# MKM34Z7 register map
Vendor: Freescale Semiconductor, Inc.; Series: Kinetis_M; File version: 1.6
CPU: CM0PLUS r0p0, little endian, no MPU, no FPU, VTOR, 2 interrupt priority bits
Registers are 8-bit, read-write, reset 0x0 unless marked. A register's access mark holds for its fields unless they carry their own. Offsets are from the block's base; [hi:lo] are bit positions; {n}, {i} and the like mark numbered series.

## SIM — System Integration Module
Base 0x4003E000; register names take the prefix SIM_
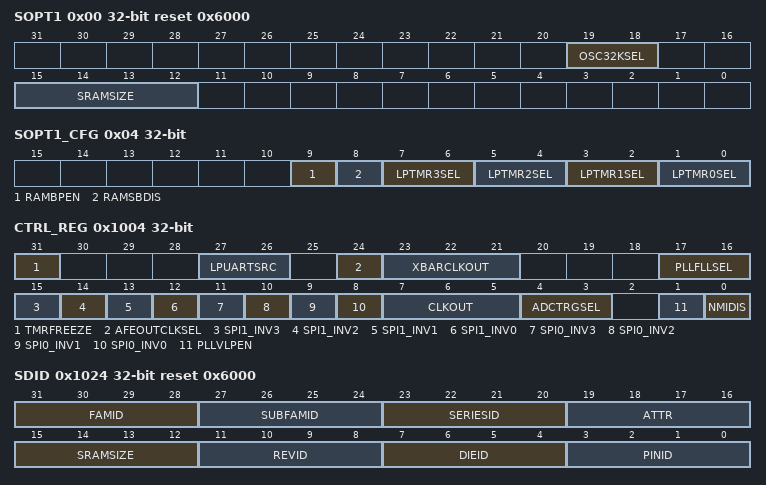
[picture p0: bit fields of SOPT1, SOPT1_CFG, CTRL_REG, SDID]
0x00 SOPT1 32-bit reset 0x6000 — System Options Register 1
  [19:18] OSC32KSEL — 32K oscillator clock select
    0=OSC32KCLK (RTC Oscillator output); 1=ERCLK32K; 2=MCGIRCLK; 3=LPO
  [15:12] SRAMSIZE ro — Returns the size of the system RAM
    6=32 KB System RAM
0x04 SOPT1_CFG 32-bit — SOPT1 Configuration Register
  [9] RAMBPEN — RAM Bitline Precharge Enable
    0=Bitline precharge of system SRAM disabled during VLPR and VLPW modes; 1=Bitline precharge of system SRAM enabled during VLPR and VLPW modes
  [8] RAMSBDIS — Disable source bias of System SRAM arrays during VLPR and VLPW modes.
    0=Source bias of System SRAM enabled during VLPR and VLPW modes; 1=Source bias of System SRAM disabled during VLPR and VLPW modes
  [7:6] LPTMR3SEL — LP Timer Channel3 Select
    0=Pad PTD5; 1=Pad PTG0; 2=Pad PTG6
  [5:4] LPTMR2SEL — LP Timer Channel2 Select
    0=Pad PTD6; 1=Pad PTF3; 2=Pad PTG5
  [3:2] LPTMR1SEL — LP Timer Channel1 Select
    0=Pad PTE4; 1=Pad PTF4; 2=Pad PTG1
  [1:0] LPTMR0SEL — LP Timer Channel0 Select
    0=CMP[0] output; 1=CMP[1] output; 2=CMP[2] output
0x1004 CTRL_REG 32-bit — System Control Register
  [31] TMRFREEZE — QTMR counters Freeze control
    0=QTMR counters operate normally; 1=QTMR counters and OFLAGs are reset. Clearing this bit will resume QTMR operation.
  [27:26] LPUARTSRC — LPUART clock Source configuration
    0=Clock disabled; 1=MCGPLLCLK/MCGFLLCLK; 2=OSCERCLK; 3=MCGIRCLK
  [24] AFEOUTCLKSEL — AFE clock output select
    0=AFE output clock is divided by AFE clock prescaler; 1=AFE output clock is NOT divided by AFE clock prescaler
  [23:21] XBARCLKOUT — XBAR clock out selection
    0=Disabled; 1=Gated Core Clk; 2=Bus Clk; 3=LPO clock from PMC; 4=IRC clock from MCG; 5=MUXed 32 kHz source (please refer to SOPT1[19:18] for possible options); 6=MHz Oscillator external reference clock; 7=PLL clock output from MCG
  [17:16] PLLFLLSEL — PLL/FLL selection
    0=MCGFLLCLK; 1=MCGPLLCLK; 2=BUSCLK; 3=OSC32KCLK (RTC Oscillator output)
  [15] SPI1_INV3 — This bit inverts the SPI1 signal output.
    0=not inverted; 1=inverts MISO
  [14] SPI1_INV2 — This bit inverts the SPI1 signal output.
    0=not inverted; 1=inverts MOSI
  [13] SPI1_INV1 — This bit inverts the SPI1 signal output.
    0=not inverted; 1=inverts SCK
  [12] SPI1_INV0 — This bit inverts the SPI1 signal output.
    0=not inverted; 1=inverts SS
  [11] SPI0_INV3 — This bit inverts the SPI0 signal output.
    0=not inverted; 1=inverts MISO
  [10] SPI0_INV2 — This bit inverts the SPI0 signal output.
    0=not inverted; 1=inverts MOSI
  [9] SPI0_INV1 — This bit inverts the SPI0 signal output.
    0=not inverted; 1=inverts SCK
  [8] SPI0_INV0 — This bit inverts the SPI0 signal output.
    0=not inverted; 1=inverts SS
  [7:5] CLKOUT — Clock out Select
    0=Disabled; 1=Gated Core Clk; 2=Bus Clk; 3=LPO clock from PMC; 4=IRC clock from MCG; 5=Muxed 32Khz source (please refer to SOPT1[19:18] for possible options); 6=MHz Oscillator external reference clock; 7=PLL clock output from MCG
  [4:3] ADCTRGSEL — SAR ADC Trigger Clock Select
    0=Bus ClockDuring Low Power Modes such as stop, the Bus clock is not available for conversion and should not be selected in case a conversion needs to be performed while in stop; 1=ADC asynchronous Clock; 2=ERCLK32K; 3=OSCCLK
  [1] PLLVLPEN — PLL VLP Enable
  [0] NMIDIS — NMI Disable
    0=NMI enabled; 1=NMI disabled
0x1024 SDID 32-bit ro reset 0x6000 (reset mask 0xFF000) — System Device Identification Register
  [31:28] FAMID — Metering family ID
    1=Device derivatives without LCD; 3=Device derivatives with LCD
  [27:24] SUBFAMID — Sub-Family ID
    0=Device derivatives with NO AFE enabled; {v}=Device derivatives with {v} AFE enabled (v=1..4)
  [23:20] SERIESID
    3=Metering Series
  [19:16] ATTR — Attribute ID
    0=M0+ core
  [15:12] SRAMSIZE
    6=32 KB SRAM
  [11:8] REVID — Revision ID
    0=First cut
  [7:4] DIEID
    0=First cut
  [3:0] PINID — Pincount identification
    5=64-pin; 8=100-pin; 9=128-pin; 10=144-pin
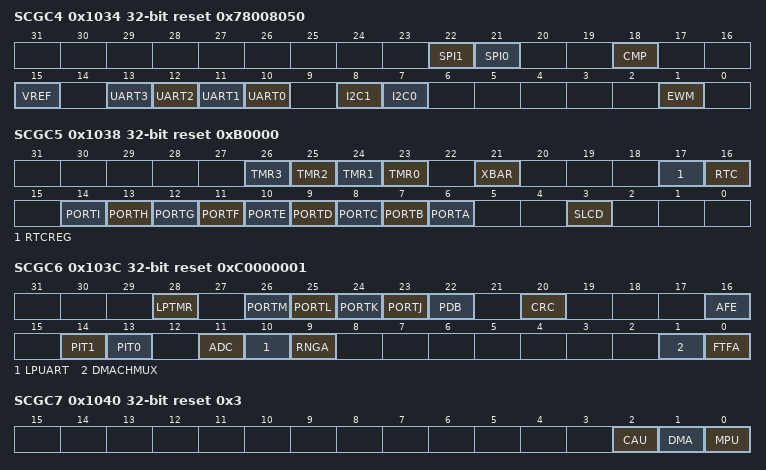
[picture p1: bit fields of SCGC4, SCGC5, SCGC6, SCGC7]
0x1034 SCGC4 32-bit reset 0x78008050 — System Clock Gating Control Register 4
  [all] fields
    0=Clock disabled; 1=Clock enabled
  [22] SPI1 — SPI1 Clock Gate Control
  [21] SPI0 — SPI0 Clock Gate Control
  [18] CMP — High Speed Comparator Clock Gate Control.
  [15] VREF — VREF Clock Gate Control
  [n+10] UART{n} (n=0..3) — UART{n} Clock Gate Control
  [8] I2C1 — I2C1 Clock Gate Control
  [7] I2C0 — I2C0 Clock Gate Control
  [1] EWM — External Watchdog Monitor Clock gate control
0x1038 SCGC5 32-bit reset 0xB0000 — System Clock Gating Control Register 5
  [all] fields
    0=Clock disabled; 1=Clock enabled
  [n+23] TMR{n} (n=0..3) — QaudTimer channel {n} Clock Gate Control
  [21] XBAR — Peripheral Crossbar Clock Gate Control
  [17] RTCREG — iRTC_REG_FILE Clock Gate Control
  [16] RTC — iRTC Clock Gate Control
  [14] PORTI — PCTLI Clock Gate Control
  [13] PORTH — PCTLH Clock Gate Control
  [12] PORTG — PCTLG Clock Gate Control
  [11] PORTF — PCTLF Clock Gate Control
  [10] PORTE — PCTLE Clock Gate Control
  [9] PORTD — PCTLD Clock Gate Control
  [8] PORTC — PCTLC Clock Gate Control
  [7] PORTB — PCTLB Clock Gate Control
  [6] PORTA — PCTLA Clock Gate Control
  [3] SLCD — Segmented LCD Clock Gate Control
0x103C SCGC6 32-bit reset 0xC0000001 — System Clock Gating Control Register 6
  [all] fields
    0=Clock disabled; 1=Clock enabled
  [28] LPTMR — LPTMR Clock Gate Control
  [26] PORTM — PCTLM Clock Gate Control
  [25] PORTL — PCTLL Clock Gate Control
  [24] PORTK — PCTLK Clock Gate Control
  [23] PORTJ — PCTLJ Clock Gate Control
  [22] PDB — PDB Clock Gate Control
  [20] CRC — Programmable CRC Clock Gate Control
  [16] AFE — AFE Clock Gate Control
  [14] PIT1 — PIT1 Clock Gate Control
  [13] PIT0 — PIT0 Clock Gate Control
  [11] ADC — SAR ADC Clock Gate Control
  [10] LPUART — LPUART Clock Gate Control
  [9] RNGA — RNGA Clock Gate Control
  [1] DMACHMUX — DMA Channel MUX Clock Gate Control
  [0] FTFA — FTFA Clock Gate Control
0x1040 SCGC7 32-bit reset 0x3 — System Clock Gating Control Register 7
  [all] fields
    0=Clock disabled; 1=Clock enabled
  [2] CAU — CAU Clock Gate control.
  [1] DMA — DMA Clock Gate control.
  [0] MPU — MPU Clock Gate control.
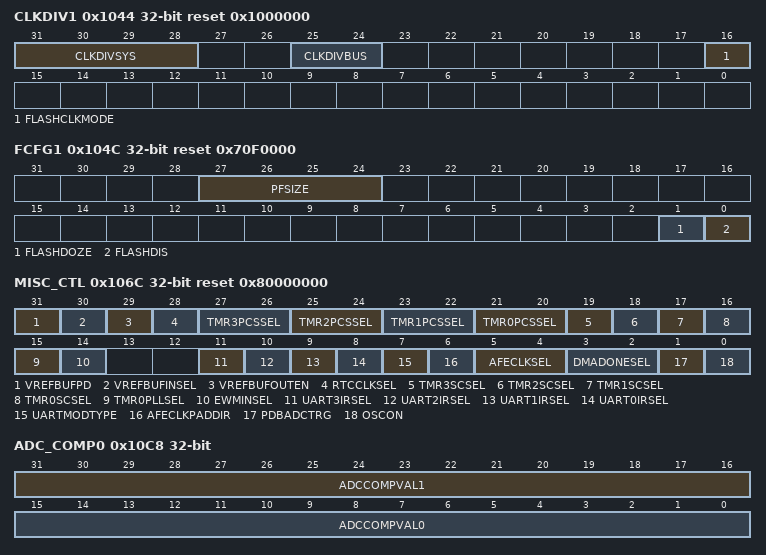
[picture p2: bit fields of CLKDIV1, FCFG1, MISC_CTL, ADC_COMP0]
0x1044 CLKDIV1 32-bit reset 0x1000000 — System Clock Divider Register 1
  [31:28] CLKDIVSYS — System Clock divider
    0=Divide by 1; 1=Divide by 2; 2=Divide by 3; 3=Divide by 4 and so on... If FOPT[0] is 0, the divider is set to div-by-8 after system reset is deasserted (after completion of system initialization sequence).
  [25:24] CLKDIVBUS — Bus Clock divider
    {v}=SYSCLK:BUSCLK = {v+1}:1 (v=0..3)
  [16] FLASHCLKMODE — Flash Clock Mode
    0=Flash Clock is the same as BUS clock; 1=Flash Clock is a half of BUS clock
0x104C FCFG1 32-bit reset 0x70F0000 — Flash Configuration Register 1
  [27:24] PFSIZE ro — Program flash size
    7=128 KB of program flash memory; 9=256 KB of program flash memory; 15=(Default)
  [1] FLASHDOZE
    0=Flash remains enabled during Wait mode; 1=Flash is disabled for the duration of Wait mode
  [0] FLASHDIS — Flash Disable
    0=Flash is enabled; 1=Flash is disabled
0x1050 FCFG2 32-bit ro reset 0x10000000 — Flash Configuration Register 2
  [30:24] MAXADDR — Max address
0x1054 UIDH 32-bit ro reset not defined — Unique Identification Register High
  [31:0] UID127_96 — Unique Identification UID[127:96]
0x1058 UIDMH 32-bit ro reset not defined — Unique Identification Register Mid-High
  [31:0] UID95_64 — Unique Identification UID[95:64]
0x105C UIDML 32-bit ro reset not defined — Unique Identification Register Mid-Low
  [31:0] UID63_32 — Unique Identification UID[63:32]
0x1060 UIDL 32-bit ro reset not defined — Unique Identification Register Low
  [31:0] UID31_0 — Unique Identification UID[31:0]
0x106C MISC_CTL 32-bit reset 0x80000000 — Miscellaneous Control Register
  [31] VREFBUFPD — VrefBuffer Power Down
    0=Buffer Enabled; 1=Buffer Powered Down
  [30] VREFBUFINSEL — VrefBuffer Input Select
    0=Internal Reference selected as Buffer Input; 1=External Reference selected as Buffer Input
  [29] VREFBUFOUTEN — VrefBuffer Output Enable
    0=Buffer does not drive PAD; 1=Buffer drives selected voltage (selected by vref_buffer_sel) on pad
  [28] RTCCLKSEL — RTC Clock select
    0=RTC OSC_32K clock selected; 1=MCGIRCLK selected
  [2n+21:2n+20] TMR{n}PCSSEL (n=0..3) — Quadtimer Channel{n} Primary Count Source Select
    0=Bus Clock; 1=Peripheral Crossbar Output [9]; 2=Peripheral Crossbar Output [10]; 3=Disabled
  [19] TMR3SCSEL — Quadtimer Channel3 Secondary Count source Select
    0=Pad PTE5 or PTD1, depending upon PCTL configuration; 1=Peripheral Crossbar (XBAR) Output[8]
  [18] TMR2SCSEL — Quadtimer Channel2 Secondary Count source Select
    0=Pad PTF7 or PTF0, depending upon PCTL configuration; 1=Peripheral Crossbar (XBAR) Output[7]
  [17] TMR1SCSEL — Quadtimer Channel1 Secondary Count source Select
    0=Pad PTG0 or PTC6, depending upon PCTL configuration; 1=Peripheral Crossbar (XBAR) Output[6]
  [16] TMR0SCSEL — Quadtimer Channel0 Secondary Count source Select
    0=Pad PTF1 or PTD5, depending upon PCTL configuration; 1=Peripheral Crossbar (XBAR) Output[5]
  [15] TMR0PLLSEL — Timer CH0 PLL clock Select
    0=Selects Bus Clock as source for the Timer CH0; 1=Selects the PLL_AFE clock as the source for Timer CH0. The PLL_AFE clock source is itself selected using the MISC_CTL[5:4]
  [14] EWMINSEL — External Watchdog Monitor Input Select
    0=Input from PAD (PTL[3], PTE[2] or PTE[3] as selected from Pinmux control ); 1=Peripheral Crossbar (XBAR) Output[32]
  [11] UART3IRSEL — UART3 IrDA Select
    0=Pad RX input (PTC[3] or PTD[7], as selected in Pinmux control) selected for RX input of UART3 and UART3 TX signal is not used for modulation; 1=UART3 selected for IrDA modulation. UART3 TX modulated by XBAR_OUT[14] and UART3 RX input connected to XBAR_OUT[13]. UARTxIRSEL cannot configure XBAR_OUT[14] and XBAR_OUT[13] automatically, and they need extra configuration in XBAR. User should configure XBAR[14:13] accordingly.
  [10] UART2IRSEL — UART2 IrDA Select
    0=Pad RX input PTI[6] or PTE[6] selected for RX input of UART2 and UART2 TX signal is not used for modulation; 1=UART2 selected for IrDA modulation. UART2 TX modulated by XBAR_OUT[14] and UART2 RX input connected to XBAR_OUT[13].UARTxIRSEL cannot configure XBAR_OUT[14] and XBAR_OUT[13] automatically, and they need extra configuration in XBAR. User should configure XBAR[14:13] accordingly.
  [9] UART1IRSEL — UART1 IrDA Select
    0=Pad RX input (PTD[2], PTI[0] or PTK[5], as selected in Pinmux control) selected for RX input of UART1 and UART1 TX signal is not used for modulation; 1=UART1 selected for IrDA modulation. UART1 TX modulated by XBAR_OUT[14] and UART1 RX input connected to XBAR_OUT[13].UARTxIRSEL cannot configure XBAR_OUT[14] and XBAR_OUT[13] automatically, and they need extra configuration in XBAR. User should configure XBAR[14:13] accordingly.
  [8] UART0IRSEL — UART0 IrDA Select
    0=Pad RX input (PTD[0], PTF[3] or PTK[3], as selected in Pinmux control) selected for RX input of UART0 and UART0 TX signal is not used for modulation; 1=UART0 selected for IrDA modulation. UART0 TX modulated by XBAR_OUT[14] and UART0 RX input connected to XBAR_OUT[13]. UARTxIRSEL cannot configure XBAR_OUT[14] and XBAR_OUT[13] automatically, and they need extra configuration in XBAR. User should configure XBAR[14:13] accordingly.
  [7] UARTMODTYPE — UART Modulation Type
    0=TypeA (OR'ed) Modulation selected for IrDA; 1=TypeB (AND'ed) Modulation selected for IrDA
  [6] AFECLKPADDIR — AFE Clock Pad Direction
    0=AFE CLK PAD is input; 1=AFE CLK PAD is output
  [5:4] AFECLKSEL — AFE Clock Source Select (SIMAFECLK selection)
    0=MCG PLL Clock selected; 1=MCG FLL Clock selected; 2=OSC Clock selected; 3=Disabled
  [3:2] DMADONESEL — DMA Done select
    {v}=DMA{v} (v=0..3)
  [1] PDBADCTRG — PDB bypass XBAR as ADC trigger
    0=XBAR to trigger ADC; 1=PDB output to trigger ADC
  [0] OSCON ro — RTC oscillator status
    0=RTC oscillator is disabled; 1=RTC oscillator is enabled
0x10C8 ADC_COMP0 32-bit ro reset not defined — ADC Compensation Register 0
  [31:16] ADCCOMPVAL1 — ADC Temperature Compensation Value 1
  [15:0] ADCCOMPVAL0 — ADC Temperature Compensation Value 0
0x10CC ADC_COMP1 32-bit ro (reset mask 0xFFFF0000) — ADC Compensation Register 1
  [15:0] ADCCOMPVAL2 — ADC Temperature Compensation Value 2
